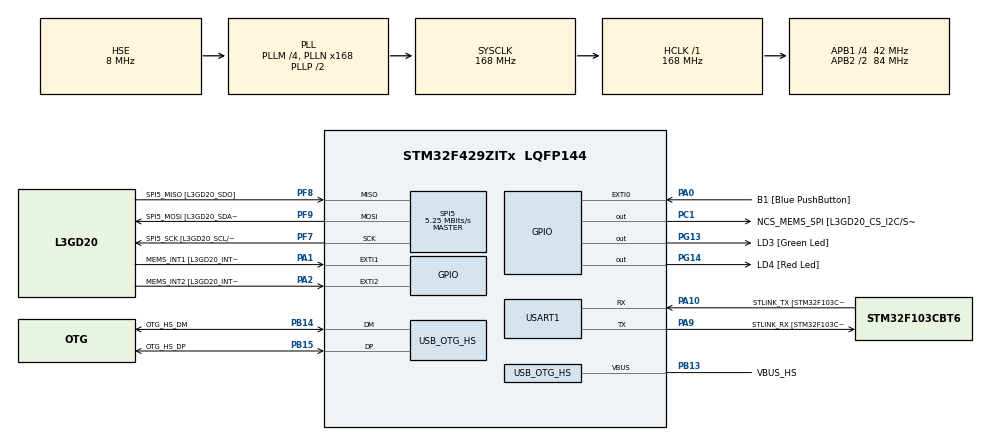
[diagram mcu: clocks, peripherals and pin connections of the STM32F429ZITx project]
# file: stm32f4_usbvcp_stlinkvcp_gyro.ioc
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Mcu.Family=STM32F4
Mcu.Name=STM32F429ZITx
Mcu.Package=LQFP144
NVIC.OTG_HS_IRQn=true\:0\:0\:false\:false\:true\:true\:true
NVIC.PriorityGroup=NVIC_PRIORITYGROUP_4
PA0/WKUP.GPIO_Label=B1 [Blue PushButton]
PA0/WKUP.GPIO_ModeDefaultEXTI=GPIO_MODE_EVT_RISING
PA0/WKUP.GPIO_PuPd=GPIO_NOPULL
PA0/WKUP.Signal=GPXTI0
PA1.GPIO_Label=MEMS_INT1 [L3GD20_INT1]
PA1.GPIO_ModeDefaultEXTI=GPIO_MODE_EVT_RISING
PA1.GPIO_PuPd=GPIO_NOPULL
PA1.Signal=GPXTI1
PA10.GPIO_Label=STLINK_TX [STM32F103CBT6_PA2]
PA10.Mode=Asynchronous
PA10.Signal=USART1_RX
PA13.GPIO_Label=SWDIO
PA13.Mode=Serial_Wire
PA13.Signal=SYS_JTMS-SWDIO
PA14.GPIO_Label=SWCLK
PA14.Mode=Serial_Wire
PA14.Signal=SYS_JTCK-SWCLK
PA2.GPIO_Label=MEMS_INT2 [L3GD20_INT2]
PA2.GPIO_ModeDefaultEXTI=GPIO_MODE_EVT_RISING
PA2.GPIO_PuPd=GPIO_NOPULL
PA2.Signal=GPXTI2
PA9.GPIO_Label=STLINK_RX [STM32F103CBT6_PA3]
PA9.Mode=Asynchronous
PA9.Signal=USART1_TX
PB13.GPIO_Label=VBUS_HS
PB13.GPIO_Mode=GPIO_MODE_INPUT
PB13.GPIO_PuPd=GPIO_NOPULL
PB13.Mode=Activate_VBUS_FS
PB13.Signal=USB_OTG_HS_VBUS
PB14.GPIO_Label=OTG_HS_DM
PB14.GPIO_Mode=GPIO_MODE_AF_PP
PB14.GPIO_PuPd=GPIO_NOPULL
PB14.GPIO_Speed=GPIO_SPEED_FREQ_LOW
PB14.Mode=Device_Only_FS
PB14.Signal=USB_OTG_HS_DM
PB15.GPIO_Label=OTG_HS_DP
PB15.GPIO_Mode=GPIO_MODE_AF_PP
PB15.GPIO_PuPd=GPIO_NOPULL
PB15.GPIO_Speed=GPIO_SPEED_FREQ_LOW
PB15.Mode=Device_Only_FS
PB15.Signal=USB_OTG_HS_DP
PC1.GPIO_Label=NCS_MEMS_SPI [L3GD20_CS_I2C/SPI]
PC1.GPIO_Mode=GPIO_MODE_OUTPUT_PP
PC1.GPIO_PuPd=GPIO_NOPULL
PC1.GPIO_Speed=GPIO_SPEED_FREQ_LOW
PC1.Signal=GPIO_Output
PF7.GPIO_Label=SPI5_SCK [L3GD20_SCL/SPC]
PF7.GPIO_Mode=GPIO_MODE_AF_PP
PF7.GPIO_PuPd=GPIO_NOPULL
PF7.GPIO_Speed=GPIO_SPEED_FREQ_LOW
PF7.Mode=Full_Duplex_Master
PF7.Signal=SPI5_SCK
PF8.GPIO_Label=SPI5_MISO [L3GD20_SDO]
PF8.GPIO_Mode=GPIO_MODE_AF_PP
PF8.GPIO_PuPd=GPIO_NOPULL
PF8.GPIO_Speed=GPIO_SPEED_FREQ_LOW
PF8.Mode=Full_Duplex_Master
PF8.Signal=SPI5_MISO
PF9.GPIO_Label=SPI5_MOSI [L3GD20_SDA/SDI/SDO]
PF9.GPIO_Mode=GPIO_MODE_AF_PP
PF9.GPIO_PuPd=GPIO_NOPULL
PF9.GPIO_Speed=GPIO_SPEED_FREQ_LOW
PF9.Mode=Full_Duplex_Master
PF9.Signal=SPI5_MOSI
PG13.GPIO_Label=LD3 [Green Led]
PG13.GPIO_Mode=GPIO_MODE_OUTPUT_PP
PG13.GPIO_PuPd=GPIO_NOPULL
PG13.GPIO_Speed=GPIO_SPEED_FREQ_LOW
PG13.Signal=GPIO_Output
PG14.GPIO_Label=LD4 [Red Led]
PG14.GPIO_Mode=GPIO_MODE_OUTPUT_PP
PG14.GPIO_PuPd=GPIO_NOPULL
PG14.GPIO_Speed=GPIO_SPEED_FREQ_LOW
PG14.Signal=GPIO_Output
PH0/OSC_IN.GPIO_Label=PH0-OSC_IN
PH0/OSC_IN.Mode=HSE-External-Oscillator
PH0/OSC_IN.Signal=RCC_OSC_IN
PH1/OSC_OUT.GPIO_Label=PH1-OSC_OUT
PH1/OSC_OUT.Mode=HSE-External-Oscillator
PH1/OSC_OUT.Signal=RCC_OSC_OUT
ProjectManager.HeapSize=0x2000
ProjectManager.StackSize=0x4000
ProjectManager.TargetToolchain=MDK-ARM V5
RCC.48MHZClocksFreq_Value=48000000
RCC.AHBFreq_Value=168000000
RCC.APB1CLKDivider=RCC_HCLK_DIV4
RCC.APB1Freq_Value=42000000
RCC.APB1TimFreq_Value=84000000
RCC.APB2CLKDivider=RCC_HCLK_DIV2
RCC.APB2Freq_Value=84000000
RCC.APB2TimFreq_Value=168000000
RCC.CortexFreq_Value=168000000
RCC.HCLKFreq_Value=168000000
RCC.HSE_VALUE=8000000
RCC.HSI_VALUE=16000000
RCC.LSE_VALUE=32768
RCC.PLLM=4
RCC.PLLN=168
RCC.PLLQ=7
RCC.PLLSAIDivR=RCC_PLLSAIDIVR_4
RCC.PLLSAIN=60
RCC.PLLSAIR=5
RCC.SYSCLKFreq_VALUE=168000000
RCC.SYSCLKSource=RCC_SYSCLKSOURCE_PLLCLK
RCC.VCOOutputFreq_Value=336000000
SPI5.BaudRatePrescaler=SPI_BAUDRATEPRESCALER_16
SPI5.CalculateBaudRate=5.25 MBits/s
SPI5.Direction=SPI_DIRECTION_2LINES
SPI5.Mode=SPI_MODE_MASTER
SPI5.VirtualType=VM_MASTER
USART1.VirtualMode=VM_ASYNC
USB_DEVICE.CLASS_NAME_HS=CDC
USB_DEVICE.VirtualMode-CDC_HS=Cdc
USB_DEVICE.VirtualModeHS=Cdc_HS
USB_OTG_HS.VirtualMode-Device_Only_FS=Device_Only_FS
VP_TIM1_VS_ClockSourceINT.Mode=Internal
VP_USB_DEVICE_VS_USB_DEVICE_CDC_HS.Mode=CDC_HS
board=32F429IDISCOVERY

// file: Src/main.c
/* USER CODE BEGIN Header */
/**
  ******************************************************************************
  * @file           : main.c
  * @brief          : Main program body
  ******************************************************************************
  * @attention
  *
  * <h2><center>&copy; Copyright (c) 2019 STMicroelectronics.
  * All rights reserved.</center></h2>
  *
  * This software component is licensed by ST under Ultimate Liberty license
  * SLA0044, the "License"; You may not use this file except in compliance with
  * the License. You may obtain a copy of the License at:
  *                             www.st.com/SLA0044
  *
  ******************************************************************************
  */
/* USER CODE END Header */

#include "main.h"
#include "gfxsimulator.h"
#include "spi.h"
#include "tim.h"
#include "usart.h"
#include "usb_device.h"
#include "gpio.h"

/* USER CODE BEGIN Includes */
#include "usbd_cdc_if.h"
#include <string.h>
/* USER CODE END Includes */

/* USER CODE BEGIN PV */
extern UART_HandleTypeDef huart1;

/* USER CODE END PV */

void SystemClock_Config(void);

int main(void)
{

  /* MCU Configuration--------------------------------------------------------*/

  /* Reset of all peripherals, Initializes the Flash interface and the Systick. */
  HAL_Init();

  /* Configure the system clock */
  SystemClock_Config();

  /* Initialize all configured peripherals */
  MX_GPIO_Init();
  MX_SPI5_Init();
  MX_TIM1_Init();
  MX_USART1_UART_Init();
  MX_USB_DEVICE_Init();
  /* USER CODE BEGIN 2 */
	char buff[] = "Hello World!\r\n";
HAL_UART_Transmit(&huart1,(uint8_t*)buff, strlen(buff),10);
  /* USER CODE END 2 */
  /* Infinite loop */
  while (1)
  {

    /* USER CODE BEGIN 3 */

		HAL_GPIO_TogglePin(LD4_GPIO_Port, LD4_Pin);
		//HAL_UART_Transmit(&huart1,(uint8_t*)buff, strlen(buff),10);

		HAL_Delay(500);
		//CDC_Transmit_HS((uint8_t*)buff,strlen(buff));
		//HAL_GPIO_TogglePin(LD3_GPIO_Port, LD3_Pin);

	}
  /* USER CODE END 3 */
}

void SystemClock_Config(void)
{
  RCC_OscInitTypeDef RCC_OscInitStruct = {0};
  RCC_ClkInitTypeDef RCC_ClkInitStruct = {0};

  /** Configure the main internal regulator output voltage
  */
  __HAL_RCC_PWR_CLK_ENABLE();
  __HAL_PWR_VOLTAGESCALING_CONFIG(PWR_REGULATOR_VOLTAGE_SCALE1);
  /** Initializes the CPU, AHB and APB busses clocks
  */
  RCC_OscInitStruct.OscillatorType = RCC_OSCILLATORTYPE_HSE;
  RCC_OscInitStruct.HSEState = RCC_HSE_ON;
  RCC_OscInitStruct.PLL.PLLState = RCC_PLL_ON;
  RCC_OscInitStruct.PLL.PLLSource = RCC_PLLSOURCE_HSE;
  RCC_OscInitStruct.PLL.PLLM = 4;
  RCC_OscInitStruct.PLL.PLLN = 168;
  RCC_OscInitStruct.PLL.PLLP = RCC_PLLP_DIV2;
  RCC_OscInitStruct.PLL.PLLQ = 7;
  if (HAL_RCC_OscConfig(&RCC_OscInitStruct) != HAL_OK)
  {
    Error_Handler();
  }
  /** Initializes the CPU, AHB and APB busses clocks
  */
  RCC_ClkInitStruct.ClockType = RCC_CLOCKTYPE_HCLK|RCC_CLOCKTYPE_SYSCLK
                              |RCC_CLOCKTYPE_PCLK1|RCC_CLOCKTYPE_PCLK2;
  RCC_ClkInitStruct.SYSCLKSource = RCC_SYSCLKSOURCE_PLLCLK;
  RCC_ClkInitStruct.AHBCLKDivider = RCC_SYSCLK_DIV1;
  RCC_ClkInitStruct.APB1CLKDivider = RCC_HCLK_DIV4;
  RCC_ClkInitStruct.APB2CLKDivider = RCC_HCLK_DIV2;

  if (HAL_RCC_ClockConfig(&RCC_ClkInitStruct, FLASH_LATENCY_5) != HAL_OK)
  {
    Error_Handler();
  }
}

/* USER CODE BEGIN 4 */
void CDC_ReceiveCallback(uint8_t* buff, uint32_t len)
{
		CDC_Transmit_HS(buff, len);
		HAL_GPIO_TogglePin(LD3_GPIO_Port, LD3_Pin);

}
/* USER CODE END 4 */

void HAL_TIM_PeriodElapsedCallback(TIM_HandleTypeDef *htim)
{
  if (htim->Instance == TIM6) {
    HAL_IncTick();
  }
}

void Error_Handler(void)
{
}

/************************ (C) COPYRIGHT STMicroelectronics *****END OF FILE****/
